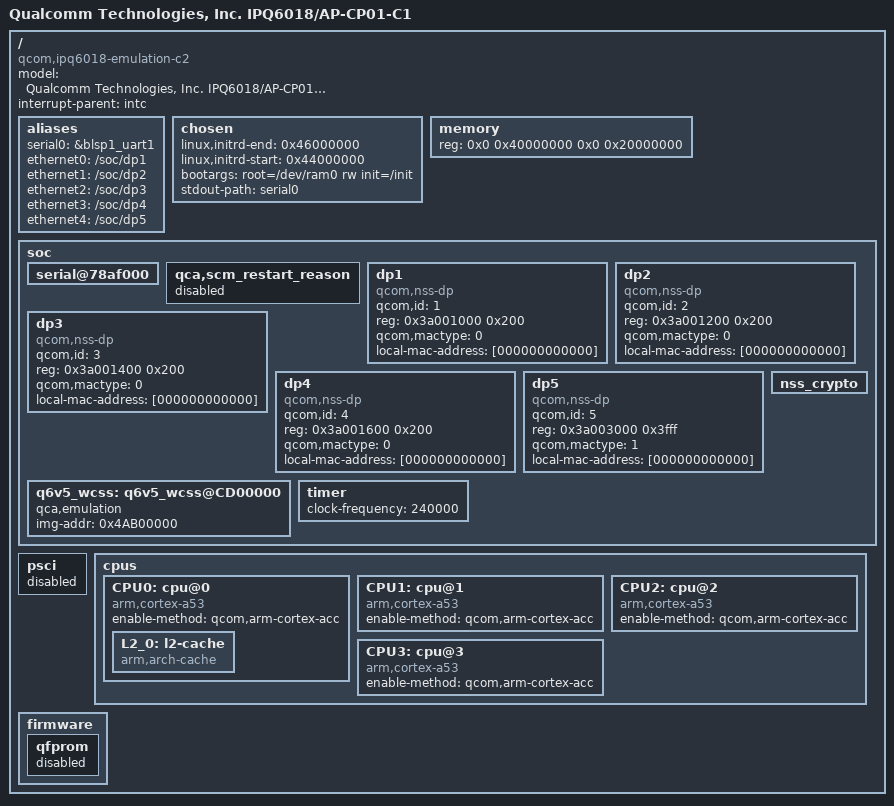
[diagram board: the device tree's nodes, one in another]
/dts-v1/;
/* Copyright (c) 2018-2019, The Linux Foundation. All rights reserved.
 *
 * Permission to use, copy, modify, and/or distribute this software for any
 * purpose with or without fee is hereby granted, provided that the above
 * copyright notice and this permission notice appear in all copies.
 *
 * THE SOFTWARE IS PROVIDED "AS IS" AND THE AUTHOR DISCLAIMS ALL WARRANTIES
 * WITH REGARD TO THIS SOFTWARE INCLUDING ALL IMPLIED WARRANTIES OF
 * MERCHANTABILITY AND FITNESS. IN NO EVENT SHALL THE AUTHOR BE LIABLE FOR
 * ANY SPECIAL, DIRECT, INDIRECT, OR CONSEQUENTIAL DAMAGES OR ANY DAMAGES
 * WHATSOEVER RESULTING FROM LOSS OF USE, DATA OR PROFITS, WHETHER IN AN
 * ACTION OF CONTRACT, NEGLIGENCE OR OTHER TORTIOUS ACTION, ARISING OUT OF
 * OR IN CONNECTION WITH THE USE OR PERFORMANCE OF THIS SOFTWARE.
 */
#include "qcom-ipq6018.dtsi"
#include "qcom-ipq6018-rpm-regulator.dtsi"
#include "qcom-ipq6018-cpr-regulator.dtsi"
#include "qcom-ipq6018-cp-cpu.dtsi"

/ {
	#address-cells = <0x2>;
	#size-cells = <0x2>;
	model = "Qualcomm Technologies, Inc. IPQ6018/AP-CP01-C1";
	compatible = "qcom,ipq6018-emulation-c2", "qcom,ipq6018";
	interrupt-parent = <&intc>;

	aliases {
		serial0 = &blsp1_uart1;
		/*
		 * Aliases as required by u-boot
		 * to patch MAC addresses
		 */
		ethernet0 = "/soc/dp1";
		ethernet1 = "/soc/dp2";
		ethernet2 = "/soc/dp3";
		ethernet3 = "/soc/dp4";
		ethernet4 = "/soc/dp5";
	};

	chosen {
		linux,initrd-end = <0x46000000>;
		linux,initrd-start = <0x44000000>;
		bootargs = "root=/dev/ram0 rw init=/init";
		stdout-path = "serial0";
	};

	memory {
		device_type = "memory";
		reg = <0x0 0x40000000 0x0 0x20000000>;
	};

	soc {
		serial@78af000 {
			status = "ok";
		};

		qca,scm_restart_reason {
			status = "disabled";
		};

		dp1 {
			device_type = "network";
			compatible = "qcom,nss-dp";
			qcom,id = <1>;
			reg = <0x3a001000 0x200>;
			qcom,mactype = <0>;
			local-mac-address = [000000000000];
		};

		dp2 {
			device_type = "network";
			compatible = "qcom,nss-dp";
			qcom,id = <2>;
			reg = <0x3a001200 0x200>;
			qcom,mactype = <0>;
			local-mac-address = [000000000000];
		};

		dp3 {
			device_type = "network";
			compatible = "qcom,nss-dp";
			qcom,id = <3>;
			reg = <0x3a001400 0x200>;
			qcom,mactype = <0>;
			local-mac-address = [000000000000];
		};

		dp4 {
			device_type = "network";
			compatible = "qcom,nss-dp";
			qcom,id = <4>;
			reg = <0x3a001600 0x200>;
			qcom,mactype = <0>;
			local-mac-address = [000000000000];
		};

		dp5 {
			device_type = "network";
			compatible = "qcom,nss-dp";
			qcom,id = <5>;
			reg = <0x3a003000 0x3fff>;
			qcom,mactype = <1>;
			local-mac-address = [000000000000];
		};

		q6v5_wcss: q6v5_wcss@CD00000 {
			qca,emulation;
			img-addr = <0x4AB00000>;
		};

		timer {
			clock-frequency = <240000>;
		};

		nss_crypto {
			status = "ok";
		};
	};

	psci {
		status = "disabled";
	};

	cpus {
		CPU0: cpu@0 {
			compatible = "arm,cortex-a53";
			enable-method = "qcom,arm-cortex-acc";

			L2_0: l2-cache {
				compatible = "arm,arch-cache";
			};
		};

		CPU1: cpu@1 {
			compatible = "arm,cortex-a53";
			enable-method = "qcom,arm-cortex-acc";
		};

		CPU2: cpu@2 {
			compatible = "arm,cortex-a53";
			enable-method = "qcom,arm-cortex-acc";
		};

		CPU3: cpu@3 {
			compatible = "arm,cortex-a53";
			enable-method = "qcom,arm-cortex-acc";
		};
	};

	firmware {
		qfprom {
			status = "disabled";
		};
	};
};
